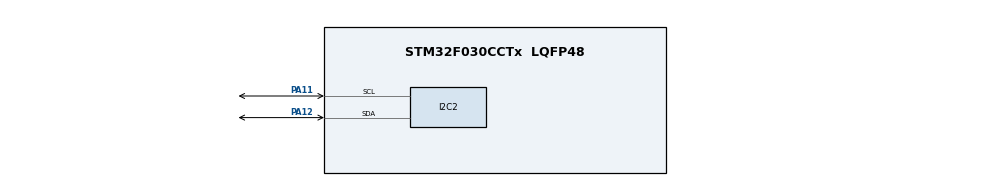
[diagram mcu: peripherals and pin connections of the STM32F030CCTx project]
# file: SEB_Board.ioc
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Mcu.Family=STM32F0
Mcu.Name=STM32F030CCTx
Mcu.Package=LQFP48
PA10.Signal=I2C1_SDA
PA11.Mode=I2C
PA11.Signal=I2C2_SCL
PA12.Mode=I2C
PA12.Signal=I2C2_SDA
PA4.Signal=SPI1_NSS
PA9.Signal=I2C1_SCL
PB12.Signal=SPI2_NSS
PB13.Signal=SPI2_SCK
PB14.Signal=SPI2_MISO
PB15.Signal=SPI2_MOSI
PB6.Signal=USART1_TX
PB7.Signal=USART1_RX
ProjectManager.HeapSize=0x200
ProjectManager.StackSize=0x400
ProjectManager.TargetToolchain=STM32CubeIDE
board=custom

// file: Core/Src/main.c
/* USER CODE BEGIN Header */
/**
  ******************************************************************************
  * @file           : main.c
  * @brief          : Main program body
  ******************************************************************************
  * @attention
  *
  * Copyright (c) 2023 STMicroelectronics.
  * All rights reserved.
  *
  * This software is licensed under terms that can be found in the LICENSE file
  * in the root directory of this software component.
  * If no LICENSE file comes with this software, it is provided AS-IS.
  *
  ******************************************************************************
  */
/* USER CODE END Header */
#include "main.h"

I2C_HandleTypeDef hi2c2;

void SystemClock_Config(void);
static void MX_GPIO_Init(void);
static void MX_I2C2_Init(void);

int main(void)
{

  /* MCU Configuration--------------------------------------------------------*/

  /* Reset of all peripherals, Initializes the Flash interface and the Systick. */
  HAL_Init();

  /* Configure the system clock */
  SystemClock_Config();

  /* Initialize all configured peripherals */
  MX_GPIO_Init();
  MX_I2C2_Init();

  /* Infinite loop */
  /* USER CODE BEGIN WHILE */
  while (1)
  {
	  HAL_GPIO_WritePin(GPIOA, uint16_t GPIO_Pin, GPIO_PinState);

    /* USER CODE END WHILE */

  }
}

void SystemClock_Config(void)
{
  RCC_OscInitTypeDef RCC_OscInitStruct = {0};
  RCC_ClkInitTypeDef RCC_ClkInitStruct = {0};

  /** Initializes the RCC Oscillators according to the specified parameters
  * in the RCC_OscInitTypeDef structure.
  */
  RCC_OscInitStruct.OscillatorType = RCC_OSCILLATORTYPE_HSI;
  RCC_OscInitStruct.HSIState = RCC_HSI_ON;
  RCC_OscInitStruct.HSICalibrationValue = RCC_HSICALIBRATION_DEFAULT;
  RCC_OscInitStruct.PLL.PLLState = RCC_PLL_NONE;
  if (HAL_RCC_OscConfig(&RCC_OscInitStruct) != HAL_OK)
  {
    Error_Handler();
  }

  /** Initializes the CPU, AHB and APB buses clocks
  */
  RCC_ClkInitStruct.ClockType = RCC_CLOCKTYPE_HCLK|RCC_CLOCKTYPE_SYSCLK
                              |RCC_CLOCKTYPE_PCLK1;
  RCC_ClkInitStruct.SYSCLKSource = RCC_SYSCLKSOURCE_HSI;
  RCC_ClkInitStruct.AHBCLKDivider = RCC_SYSCLK_DIV1;
  RCC_ClkInitStruct.APB1CLKDivider = RCC_HCLK_DIV1;

  if (HAL_RCC_ClockConfig(&RCC_ClkInitStruct, FLASH_LATENCY_0) != HAL_OK)
  {
    Error_Handler();
  }
}

static void MX_I2C2_Init(void)
{

  hi2c2.Instance = I2C2;
  hi2c2.Init.Timing = 0x2000090E;
  hi2c2.Init.OwnAddress1 = 0;
  hi2c2.Init.AddressingMode = I2C_ADDRESSINGMODE_7BIT;
  hi2c2.Init.DualAddressMode = I2C_DUALADDRESS_DISABLE;
  hi2c2.Init.OwnAddress2 = 0;
  hi2c2.Init.OwnAddress2Masks = I2C_OA2_NOMASK;
  hi2c2.Init.GeneralCallMode = I2C_GENERALCALL_DISABLE;
  hi2c2.Init.NoStretchMode = I2C_NOSTRETCH_DISABLE;
  if (HAL_I2C_Init(&hi2c2) != HAL_OK)
  {
    Error_Handler();
  }

  /** Configure Analogue filter
  */
  if (HAL_I2CEx_ConfigAnalogFilter(&hi2c2, I2C_ANALOGFILTER_ENABLE) != HAL_OK)
  {
    Error_Handler();
  }

  /** Configure Digital filter
  */
  if (HAL_I2CEx_ConfigDigitalFilter(&hi2c2, 0) != HAL_OK)
  {
    Error_Handler();
  }

}

static void MX_GPIO_Init(void)
{
  GPIO_InitTypeDef GPIO_InitStruct = {0};

  /* GPIO Ports Clock Enable */
  __HAL_RCC_GPIOA_CLK_ENABLE();
  __HAL_RCC_GPIOB_CLK_ENABLE();

  /*Configure GPIO pin : PA4 */
  GPIO_InitStruct.Pin = GPIO_PIN_4;
  GPIO_InitStruct.Mode = GPIO_MODE_AF_PP;
  GPIO_InitStruct.Pull = GPIO_NOPULL;
  GPIO_InitStruct.Speed = GPIO_SPEED_FREQ_HIGH;
  GPIO_InitStruct.Alternate = GPIO_AF0_SPI1;
  HAL_GPIO_Init(GPIOA, &GPIO_InitStruct);

  /*Configure GPIO pins : PB12 PB13 PB14 PB15 */
  GPIO_InitStruct.Pin = GPIO_PIN_12|GPIO_PIN_13|GPIO_PIN_14|GPIO_PIN_15;
  GPIO_InitStruct.Mode = GPIO_MODE_AF_PP;
  GPIO_InitStruct.Pull = GPIO_NOPULL;
  GPIO_InitStruct.Speed = GPIO_SPEED_FREQ_HIGH;
  GPIO_InitStruct.Alternate = GPIO_AF0_SPI2;
  HAL_GPIO_Init(GPIOB, &GPIO_InitStruct);

  /*Configure GPIO pins : PA9 PA10 */
  GPIO_InitStruct.Pin = GPIO_PIN_9|GPIO_PIN_10;
  GPIO_InitStruct.Mode = GPIO_MODE_AF_OD;
  GPIO_InitStruct.Pull = GPIO_NOPULL;
  GPIO_InitStruct.Speed = GPIO_SPEED_FREQ_HIGH;
  GPIO_InitStruct.Alternate = GPIO_AF4_I2C1;
  HAL_GPIO_Init(GPIOA, &GPIO_InitStruct);

  /*Configure GPIO pins : PB6 PB7 */
  GPIO_InitStruct.Pin = GPIO_PIN_6|GPIO_PIN_7;
  GPIO_InitStruct.Mode = GPIO_MODE_AF_PP;
  GPIO_InitStruct.Pull = GPIO_NOPULL;
  GPIO_InitStruct.Speed = GPIO_SPEED_FREQ_HIGH;
  GPIO_InitStruct.Alternate = GPIO_AF0_USART1;
  HAL_GPIO_Init(GPIOB, &GPIO_InitStruct);

}

void Error_Handler(void)
{
  __disable_irq();
  while (1)
  {
  }
}
